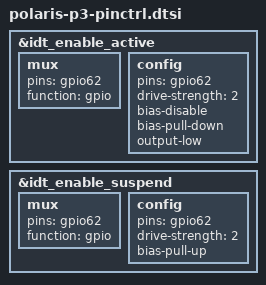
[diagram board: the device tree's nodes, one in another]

/* Copyright (c) 2016-2017, The Linux Foundation. All rights reserved.
 * Copyright (C) 2018 XiaoMi, Inc.
 *
 * This program is free software; you can redistribute it and/or modify
 * it under the terms of the GNU General Public License version 2 and
 * only version 2 as published by the Free Software Foundation.
 *
 * This program is distributed in the hope that it will be useful,
 * but WITHOUT ANY WARRANTY; without even the implied warranty of
 * MERCHANTABILITY or FITNESS FOR A PARTICULAR PURPOSE.  See the
 * GNU General Public License for more details.
 */
#include "polaris-p2-pinctrl.dtsi"

&idt_enable_active {
	/* active state */
	mux {
		/* GPIO 62 idt enable pin */
		pins = "gpio62";
		function = "gpio";
	};

	config {
		pins = "gpio62";
		drive-strength = <2>;
		bias-disable;
		bias-pull-down;
		output-low;
	};
};

&idt_enable_suspend {
	/* sleep state */
	mux {
		/* GPIO 62 idt enable pin */
		pins = "gpio62";
		function = "gpio";
	};

	config {
		pins = "gpio62";
		drive-strength = <2>;
		bias-pull-up;
	};
};
